# nrf54ls05b_enga_application register map
Vendor: Nordic Semiconductor; Series: nrf54l; File version: 1
CPU: CM33 r0p4, little endian, no MPU, no FPU, 3 interrupt priority bits, 270 interrupts
Registers are 32-bit, read-write, reset 0x0 unless marked. A register's access mark holds for its fields unless they carry their own. Offsets are from the block's base; [hi:lo] are bit positions; lines under a group give offsets from that group; {n}, {i} and the like mark numbered series; 'fields as' and 'values as' point back to an identical list.

## GLOBAL_GPIOINTERNALP1 — GPIO Internal
Base 0x400D9E00
Same registers: GLOBAL_GPIOINTERNALP0 0x4010BE00
0x40 LATCHCLRWAITCNT reset 0x2 — Select the number of wait cycles inserted on the bus when a LATCH register is cleared.
  [1:0] LATCHCLRWAITCNT
0x44 FORCELDETECTLOWCNT reset 0x8 — Select the number of cycles that LDETECT is forced low after clearing a LATCH register.
  [3:0] FORCELDETECTLOWCNT
0x48 RESET — Reset all GPIO registers.
  [0] RESET
    1=RESET (Trigger reset); 0=NA (No effect)
0x4C SENSECONFIGCHANGECNT reset 0x3 — Selects the number of cycles before the SENSE configuration takes effect when it is changed. Setting this register lower than the reset value can lead to unwanted LATCH set when SENSE and INPUT fields (PIN[n].CNF) are changed simultaneously.
  [2:0] SENSECONFIGCHANGECNT — Selects the number of cycles before the SENSE configuration takes effect when it is changed.
0x160 PCGC group — Unspecified
  {0x20+4j} PENALTY[{j}] (j=0..3) ro — Description collection: Penalty level for power/clock pair n
    [1:0] PENALTY — Penalty level
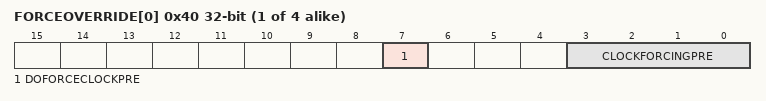
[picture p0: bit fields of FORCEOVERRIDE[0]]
  {0x40+4j} FORCEOVERRIDE[{j}] (j=0..3) ro — Description collection: Force override of power/clock pair n
    [7] DOFORCECLOCKPRE, [3:0] CLOCKFORCINGPRE

## GLOBAL_PCGCM20 — PCGC Master 0
Base 0x400E7000
Same registers: GLOBAL_PCGCM30 0x4013F000
{0xE0+4i} SETPWRCONTHRESHOLDBASE[{i}] (i=0..2) — Description collection: Set power consumption threshold base for power source / regulator n
  [3:0] SETPWRCONTHRESHOLDBASE
{0x100+4i} SETPOWERCONSUMPTIONBASE[{i}] (i=0..1) — Description collection: Set power consumption base for power/clock pair n
  [3:0] POWERREQUIREMENT
0xC00 UNLOCKBACKDOORS
  [15:0] UNLOCKBACKDOORS — Write: 0x00009375 to lock/unlock backdoors Read: 0x00000001 if backdoors is enabled Read: 0x00000000 if backdoors is disabled
0xC04 ENABLEPOWERREGFORCE
  [2:0] ENABLEPOWERREGFORCE
0xC08 POWERREGFORCE — Force reg
  [2:0] POWERREGFORCEREG
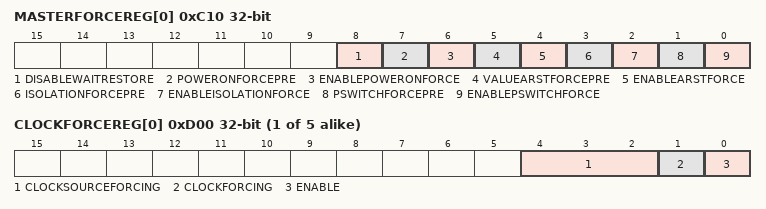
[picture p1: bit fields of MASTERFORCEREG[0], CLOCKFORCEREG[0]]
{0xC10+4i} MASTERFORCEREG[{i}] (i=0..0) — Description collection: Force reg
  [8] DISABLEWAITRESTORE — Turn off waiting for arst deactivation before retention restore
    1=Disable (Turn off waiting for arst deactivation before retention restore); 0=Enable (Wait for arst deactivation before retention restore)
  [7] POWERONFORCEPRE
  [6] ENABLEPOWERONFORCE
  [5] VALUEARSTFORCEPRE
  [4] ENABLEARSTFORCE
  [3] ISOLATIONFORCEPRE
  [2] ENABLEISOLATIONFORCE
  [1] PSWITCHFORCEPRE
  [0] ENABLEPSWITCHFORCE
{0xD00+4i} CLOCKFORCEREG[{i}] (i=0..4) — Description collection: Force clock n
  [4:2] CLOCKSOURCEFORCING
  [1] CLOCKFORCING
  [0] ENABLE — Enable clock forcing

## GLOBAL_POWER — Power control
Base 0x4010E000; alternate view of GLOBAL_CLOCK
0x30 TASKS_CONSTLAT wo — Enable Constant Latency mode When going to sleep: CPU is clock gated, but regulators, oscillators and clock tree is kept on.
  [0] TASKS_CONSTLAT
    1=Trigger task
0x34 TASKS_LOWPWR wo — Enable Low-power mode (variable latency) When going to sleep: Oscillators are switched off (if nothing else is requesting clocks). Regulators are switched off (if nothing else is requesting power).
  [0] TASKS_LOWPWR
    1=Trigger task
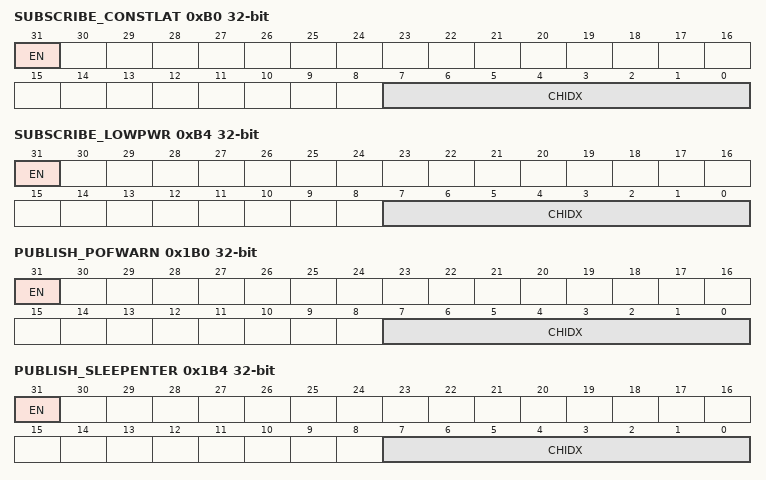
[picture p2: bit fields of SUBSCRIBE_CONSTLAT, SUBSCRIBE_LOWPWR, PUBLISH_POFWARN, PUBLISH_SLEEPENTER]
0xB0 SUBSCRIBE_CONSTLAT — Subscribe configuration for task CONSTLAT
  [31] EN
    0=Disabled (Disable subscription); 1=Enabled (Enable subscription)
  [7:0] CHIDX — DPPI channel that task CONSTLAT will subscribe to
0xB4 SUBSCRIBE_LOWPWR — Subscribe configuration for task LOWPWR
  [31] EN
    values as SUBSCRIBE_CONSTLAT.EN
  [7:0] CHIDX — DPPI channel that task LOWPWR will subscribe to
0x130 EVENTS_POFWARN — Power failure warning
  [0] EVENTS_POFWARN
    0=NotGenerated (Event not generated); 1=Generated (Event generated)
0x134 EVENTS_SLEEPENTER — CPU entered WFI/WFE sleep
  [0] EVENTS_SLEEPENTER
    values as EVENTS_POFWARN.EVENTS_POFWARN
0x138 EVENTS_SLEEPEXIT — CPU exited WFI/WFE sleep
  [0] EVENTS_SLEEPEXIT
    values as EVENTS_POFWARN.EVENTS_POFWARN
0x1B0 PUBLISH_POFWARN — Publish configuration for event POFWARN
  [31] EN
    0=Disabled (Disable publishing); 1=Enabled (Enable publishing)
  [7:0] CHIDX — DPPI channel that event POFWARN will publish to
0x1B4 PUBLISH_SLEEPENTER — Publish configuration for event SLEEPENTER
  [31] EN
    values as PUBLISH_POFWARN.EN
  [7:0] CHIDX — DPPI channel that event SLEEPENTER will publish to
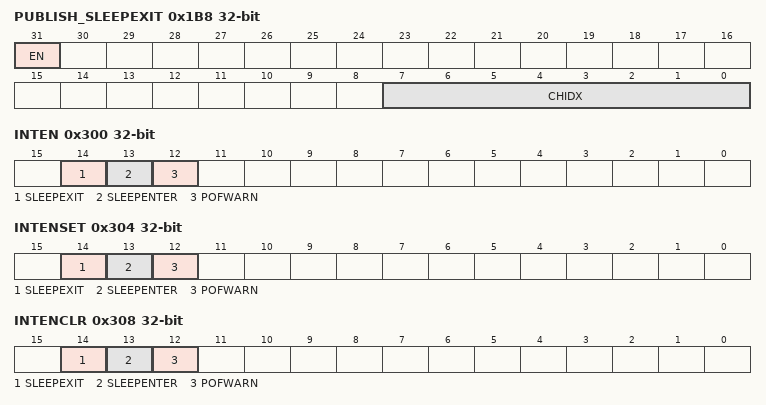
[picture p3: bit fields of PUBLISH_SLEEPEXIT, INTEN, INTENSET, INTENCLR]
0x1B8 PUBLISH_SLEEPEXIT — Publish configuration for event SLEEPEXIT
  [31] EN
    values as PUBLISH_POFWARN.EN
  [7:0] CHIDX — DPPI channel that event SLEEPEXIT will publish to
0x300 INTEN — Enable or disable interrupt
  [all] fields
    0=Disabled; 1=Enabled
  [14] SLEEPEXIT — Enable or disable interrupt for event SLEEPEXIT
  [13] SLEEPENTER — Enable or disable interrupt for event SLEEPENTER
  [12] POFWARN — Enable or disable interrupt for event POFWARN
0x304 INTENSET — Enable interrupt
  [all] fields
    on read: 0=Disabled (Read: Disabled); 1=Enabled (Read: Enabled) | on write: 1=Set (Enable)
  [14] SLEEPEXIT — Write '1' to enable interrupt for event SLEEPEXIT
  [13] SLEEPENTER — Write '1' to enable interrupt for event SLEEPENTER
  [12] POFWARN — Write '1' to enable interrupt for event POFWARN
0x308 INTENCLR — Disable interrupt
  [all] fields
    on read: 0=Disabled (Read: Disabled); 1=Enabled (Read: Enabled) | on write: 1=Clear (Disable)
  [14] SLEEPEXIT — Write '1' to disable interrupt for event SLEEPEXIT
  [13] SLEEPENTER — Write '1' to disable interrupt for event SLEEPENTER
  [12] POFWARN — Write '1' to disable interrupt for event POFWARN
{0x500+4i} GPREGRET[{i}] (i=0..1) — Description collection: General purpose retention register
  [7:0] GPREGRET — General purpose retention register
0x520 CONSTLATSTAT ro — Status of constant latency
  [0] STATUS
    0=Disable (Constant latency disabled); 1=Enable (Constant latency enabled)

## GLOBAL_RESET — Reset control
Base 0x4010E000; alternate view of GLOBAL_CLOCK
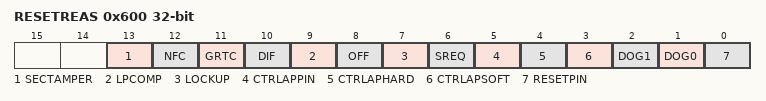
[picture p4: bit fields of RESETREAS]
0x600 RESETREAS — Reset reason
  [all] fields
    0=NotDetected; 1=Detected
  [13] SECTAMPER — Reset due to illegal tampering of the device
  [12] NFC — Reset after wakeup from System OFF mode due to NFC field being detected
  [11] GRTC — Reset due to wakeup from GRTC
  [10] DIF — Reset triggered by Debug Interface
  [9] LPCOMP — Reset due to wakeup from System OFF mode when wakeup is triggered by ANADETECT signal from LPCOMP
  [8] OFF — Reset due to wakeup from System OFF mode when wakeup is triggered by DETECT signal from GPIO
  [7] LOCKUP — Reset from CPU lockup detected
  [6] SREQ — Reset from soft reset detected
  [5] CTRLAPPIN — Reset due to CTRL-AP pin reset
  [4] CTRLAPHARD — Reset due to CTRL-AP hard reset
  [3] CTRLAPSOFT — Soft reset from CTRL-AP detected
  [2] DOG1 — Reset from watchdog timer 1 detected
  [1] DOG0 — Reset from watchdog timer 0 detected
  [0] RESETPIN — Reset from pin reset detected
